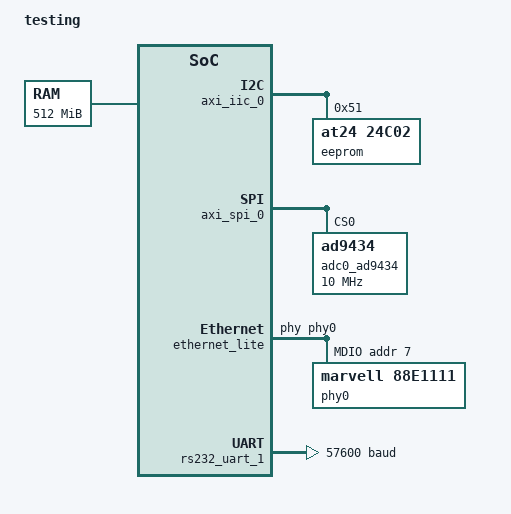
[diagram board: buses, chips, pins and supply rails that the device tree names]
/*
 * Device Tree Generator version: 1.3
 *
 * (C) Copyright 2007-2008 Xilinx, Inc.
 * (C) Copyright 2007-2009 Michal Simek
 *
 * Michal SIMEK <monstr@monstr.eu>
 *
 * This program is free software; you can redistribute it and/or
 * modify it under the terms of the GNU General Public License as
 * published by the Free Software Foundation; either version 2 of
 * the License, or (at your option) any later version.
 *
 * This program is distributed in the hope that it will be useful,
 * but WITHOUT ANY WARRANTY; without even the implied warranty of
 * MERCHANTABILITY or FITNESS FOR A PARTICULAR PURPOSE. See the
 * GNU General Public License for more details.
 *
 * You should have received a copy of the GNU General Public License
 * along with this program; if not, write to the Free Software
 * Foundation, Inc., 59 Temple Place, Suite 330, Boston,
 * MA 02111-1307 USA
 *
 * CAUTION: This file is automatically generated by libgen.
 * Version: Xilinx EDK 14.4 EDK_P.49d
 *
 * XPS project directory: device-tree_bsp_0
 */

/dts-v1/;
/ {
	#address-cells = <1>;
	#size-cells = <1>;
	compatible = "xlnx,microblaze";
	model = "testing";
	aliases {
		ethernet0 = &ethernet_lite;
		serial0 = &rs232_uart_1;
	} ;
	chosen {
		bootargs = "console=ttyS0 root=/dev/ram";
	} ;

	clocks {
// 		ad9517_ref_clk: clock@0 {
// 			#clock-cells = <0>;
// 			compatible = "fixed-clock";
// 			clock-frequency = <30720000>;
// 			clock-output-names = "refclk";
// 		};
// 		ad9517_clkin: clock@1 {
// 			#clock-cells = <0>;
// 			compatible = "fixed-clock";
// 			clock-frequency = <250000000>;
// 			clock-output-names = "clkin";
// 		};
		ad9434_clk: clock@2 {
			#clock-cells = <0>;
			compatible = "fixed-clock";
			clock-frequency = <500000000>;
			clock-output-names = "clkin";
		};

	};

	cpus {
		#address-cells = <1>;
		#cpus = <0x1>;
		#size-cells = <0>;
		microblaze_0: cpu@0 {
			clock-frequency = <100000000>;
			compatible = "xlnx,microblaze-8.30.a";
			d-cache-baseaddr = <0xc0000000>;
			d-cache-highaddr = <0xdfffffff>;
			d-cache-line-size = <0x10>;
			d-cache-size = <0x4000>;
			device_type = "cpu";
			i-cache-baseaddr = <0xc0000000>;
			i-cache-highaddr = <0xdfffffff>;
			i-cache-line-size = <0x20>;
			i-cache-size = <0x4000>;
			model = "microblaze,8.30.a";
			reg = <0>;
			timebase-frequency = <100000000>;
			xlnx,addr-tag-bits = <0xf>;
			xlnx,allow-dcache-wr = <0x1>;
			xlnx,allow-icache-wr = <0x1>;
			xlnx,area-optimized = <0x0>;
			xlnx,avoid-primitives = <0x0>;
			xlnx,branch-target-cache-size = <0x0>;
			xlnx,cache-byte-size = <0x4000>;
			xlnx,d-axi = <0x1>;
			xlnx,d-lmb = <0x1>;
			xlnx,d-plb = <0x0>;
			xlnx,data-size = <0x20>;
			xlnx,dcache-addr-tag = <0xf>;
			xlnx,dcache-always-used = <0x1>;
			xlnx,dcache-byte-size = <0x4000>;
			xlnx,dcache-data-width = <0x0>;
			xlnx,dcache-force-tag-lutram = <0x0>;
			xlnx,dcache-interface = <0x0>;
			xlnx,dcache-line-len = <0x4>;
			xlnx,dcache-use-fsl = <0x0>;
			xlnx,dcache-use-writeback = <0x0>;
			xlnx,dcache-victims = <0x0>;
			xlnx,debug-enabled = <0x1>;
			xlnx,div-zero-exception = <0x1>;
			xlnx,dynamic-bus-sizing = <0x1>;
			xlnx,ecc-use-ce-exception = <0x0>;
			xlnx,edge-is-positive = <0x1>;
			xlnx,endianness = <0x1>;
			xlnx,family = "virtex6";
			xlnx,fault-tolerant = <0x0>;
			xlnx,fpu-exception = <0x0>;
			xlnx,freq = <0x5f5e100>;
			xlnx,fsl-data-size = <0x20>;
			xlnx,fsl-exception = <0x0>;
			xlnx,fsl-links = <0x0>;
			xlnx,i-axi = <0x0>;
			xlnx,i-lmb = <0x1>;
			xlnx,i-plb = <0x0>;
			xlnx,icache-always-used = <0x1>;
			xlnx,icache-data-width = <0x0>;
			xlnx,icache-force-tag-lutram = <0x0>;
			xlnx,icache-interface = <0x0>;
			xlnx,icache-line-len = <0x8>;
			xlnx,icache-streams = <0x1>;
			xlnx,icache-use-fsl = <0x0>;
			xlnx,icache-victims = <0x8>;
			xlnx,ill-opcode-exception = <0x1>;
			xlnx,instance = "microblaze_0";
			xlnx,interconnect = <0x2>;
			xlnx,interconnect-m-axi-dc-read-issuing = <0x2>;
			xlnx,interconnect-m-axi-dc-write-issuing = <0x20>;
			xlnx,interconnect-m-axi-dp-read-issuing = <0x1>;
			xlnx,interconnect-m-axi-dp-write-issuing = <0x1>;
			xlnx,interconnect-m-axi-ic-read-issuing = <0x8>;
			xlnx,interconnect-m-axi-ip-read-issuing = <0x1>;
			xlnx,interrupt-is-edge = <0x0>;
			xlnx,lockstep-slave = <0x0>;
			xlnx,mmu-dtlb-size = <0x4>;
			xlnx,mmu-itlb-size = <0x2>;
			xlnx,mmu-privileged-instr = <0x0>;
			xlnx,mmu-tlb-access = <0x3>;
			xlnx,mmu-zones = <0x2>;
			xlnx,number-of-pc-brk = <0x1>;
			xlnx,number-of-rd-addr-brk = <0x0>;
			xlnx,number-of-wr-addr-brk = <0x0>;
			xlnx,opcode-0x0-illegal = <0x1>;
			xlnx,optimization = <0x0>;
			xlnx,pc-width = <0x20>;
			xlnx,pvr = <0x2>;
			xlnx,pvr-user1 = <0x0>;
			xlnx,pvr-user2 = <0x0>;
			xlnx,reset-msr = <0x0>;
			xlnx,sco = <0x0>;
			xlnx,stream-interconnect = <0x0>;
			xlnx,unaligned-exceptions = <0x1>;
			xlnx,use-barrel = <0x1>;
			xlnx,use-branch-target-cache = <0x0>;
			xlnx,use-dcache = <0x1>;
			xlnx,use-div = <0x1>;
			xlnx,use-ext-brk = <0x1>;
			xlnx,use-ext-nm-brk = <0x1>;
			xlnx,use-extended-fsl-instr = <0x0>;
			xlnx,use-fpu = <0x0>;
			xlnx,use-hw-mul = <0x2>;
			xlnx,use-icache = <0x1>;
			xlnx,use-interrupt = <0x1>;
			xlnx,use-mmu = <0x3>;
			xlnx,use-msr-instr = <0x1>;
			xlnx,use-pcmp-instr = <0x1>;
			xlnx,use-reorder-instr = <0x1>;
			xlnx,use-stack-protection = <0x0>;
		} ;
	} ;
	ddr3_sdram: memory@c0000000 {
		device_type = "memory";
		reg = < 0xc0000000 0x20000000 >;
	} ;
	axi4lite_0: axi@0 {
		#address-cells = <1>;
		#size-cells = <1>;
		compatible = "xlnx,axi-interconnect-1.06.a", "simple-bus";
		ranges ;
		axi_ad9434_0: cf-ad9434@73000000 {
			compatible = "xlnx,axi-ad9434-1.00.a";
			reg = < 0x73000000 0x10000 >;
			dmas = <&axi_dma_0 0>;
			dma-names = "rx";
			spibus-connected = <&adc0_ad9434>;
			xlnx,cf-buftype = <0x1>;
			xlnx,dphase-timeout = <0x8>;
			xlnx,family = "virtex6";
			xlnx,iodelay-group = "adc_if_delay_group";
			xlnx,num-mem = <0x1>;
			xlnx,num-reg = <0x1>;
			xlnx,s-axi-min-size = <0x1ff>;
			xlnx,slv-awidth = <0x20>;
			xlnx,slv-dwidth = <0x20>;
			xlnx,use-wstrb = <0x0>;
		} ;
		axi_dma_0: axidma@41e00000 {
			#address-cells = <1>;
			#size-cells = <1>;
			#dma-cells = <1>;
			compatible = "xlnx,axi-dma";
			ranges = < 0x41e00000 0x41e00000 0x10000 >;
			reg = < 0x41e00000 0x10000 >;
//			xlnx,sg-include-stscntrl-strm = <0x0>;
			dma-channel@41e00030 {
				compatible = "xlnx,axi-dma-s2mm-channel";
				interrupt-parent = <&axi_intc_0>;
				interrupts = < 3 2 >;
				xlnx,datawidth = <0x40>;
				xlnx,include-dre = <0x0>;
			} ;
		} ;

		/* LCD Display */

		axi_gpio_0: gpio@40000000 {
			compatible = "xlnx,axi-xlnx-lcd-1.00.a";
			reg = < 0x40000000 0x8 >;
			xlnx,all-inputs = <0x0>;
			xlnx,dout-default = <0x0>;
			xlnx,family = "virtex6";
			xlnx,gpio-width = <0x7>;
			xlnx,instance = "axi_gpio_0";
			xlnx,interrupt-present = <0x0>;
			xlnx,is-dual = <0x0>;
			xlnx,tri-default = <0xffffffff>;
		} ;

		axi_iic_0: i2c@40800000 {
			compatible = "xlnx,axi-iic-1.02.a", "xlnx,xps-iic-2.00.a";
			interrupt-parent = <&axi_intc_0>;
			interrupts = < 0 2 >;
			reg = < 0x40800000 0x10000 >;
			xlnx,family = "virtex6";
			xlnx,gpo-width = <0x1>;
			xlnx,iic-freq = <0x186a0>;
			xlnx,instance = "axi_iic_0";
			xlnx,s-axi-aclk-freq-hz = <0x5f5e100>;
			xlnx,scl-inertial-delay = <0x5>;
			xlnx,sda-inertial-delay = <0x5>;
			xlnx,sda-level = <0x1>;
			xlnx,ten-bit-adr = <0x0>;
			eeprom@51 {
				compatible = "at24,24c02";
				reg = <0x51>;
			};
		} ;
		axi_intc_0: interrupt-controller@41200000 {
			#interrupt-cells = <0x2>;
			compatible = "xlnx,axi-intc-1.03.a", "xlnx,xps-intc-1.00.a";
			interrupt-controller ;
			reg = < 0x41200000 0x10000 >;
			xlnx,kind-of-intr = <0x60>;
			xlnx,num-intr-inputs = <0x7>;
		} ;
		axi_spi_0: spi@40a00000 {
			compatible = "xlnx,axi-spi-1.02.a", "xlnx,xps-spi-2.00.a";
			interrupt-parent = <&axi_intc_0>;
			interrupts = < 2 2 >;
			reg = < 0x40a00000 0x10000 >;
			xlnx,family = "virtex6";
			xlnx,fifo-exist = <0x1>;
			xlnx,instance = "axi_spi_0";
			xlnx,num-ss-bits = <0x2>;
			xlnx,num-transfer-bits = <0x8>;
			xlnx,sck-ratio = <0x20>;

// 			clk_ad9517: ad9517@1 {
// 				#address-cells = <1>;
// 				#size-cells = <0>;
// 				#clock-cells = <0>;
// 				compatible = "ad9517-4";
// 				firmware = "ad9517-ad9434.stp";
// 				reg = <1>;
// 				spi-max-frequency = <10000000>;
// 				//spi-3wire;
// 				clocks = <&ad9517_ref_clk>, <&ad9517_clkin>;
// 				clock-names = "refclk", "clkin";
// 				clock-output-names = "out0", "out1", "out2", "out3", "out4", "out5", "out6", "out7";
// 			};

			adc0_ad9434: ad9434@0 {
				#address-cells = <1>;
				#size-cells = <0>;
				compatible = "ad9434";
				reg = <0>;
				spi-max-frequency = <10000000>;
				clocks = <&ad9434_clk 0>;
				clock-names = "clkin";
			};

		} ;
		axi_timer_0: timer@41c00000 {
			clock-frequency = <100000000>;
			compatible = "xlnx,axi-timer-1.03.a", "xlnx,xps-timer-1.00.a";
			interrupt-parent = <&axi_intc_0>;
			interrupts = < 4 2 >;
			reg = < 0x41c00000 0x10000 >;
			xlnx,count-width = <0x20>;
			xlnx,family = "virtex6";
			xlnx,gen0-assert = <0x1>;
			xlnx,gen1-assert = <0x1>;
			xlnx,instance = "axi_timer_0";
			xlnx,one-timer-only = <0x0>;
			xlnx,trig0-assert = <0x1>;
			xlnx,trig1-assert = <0x1>;
		} ;
		debug_module: debug@74800000 {
			compatible = "xlnx,mdm-2.10.a";
			reg = < 0x74800000 0x10000 >;
			xlnx,family = "virtex6";
			xlnx,interconnect = <0x2>;
			xlnx,jtag-chain = <0x2>;
			xlnx,mb-dbg-ports = <0x1>;
			xlnx,use-bscan = <0x0>;
			xlnx,use-uart = <0x1>;
		} ;
		ethernet_lite: ethernet@40e00000 {
			compatible = "xlnx,axi-ethernetlite-1.01.b", "xlnx,xps-ethernetlite-1.00.a";
			device_type = "network";
			interrupt-parent = <&axi_intc_0>;
			interrupts = < 5 0 >;
			local-mac-address = [ 00 0a 35 b1 22 00 ];
			phy-handle = <&phy0>;
			reg = < 0x40e00000 0x10000 >;
			xlnx,duplex = <0x1>;
			xlnx,family = "virtex6";
			xlnx,include-global-buffers = <0x0>;
			xlnx,include-internal-loopback = <0x0>;
			xlnx,include-mdio = <0x1>;
			xlnx,include-phy-constraints = <0x1>;
			xlnx,instance = "Ethernet_Lite";
			xlnx,interconnect-s-axi-read-acceptance = <0x1>;
			xlnx,interconnect-s-axi-write-acceptance = <0x1>;
			xlnx,rx-ping-pong = <0x0>;
			xlnx,s-axi-aclk-period-ps = <0x2710>;
			xlnx,s-axi-id-width = <0x1>;
			xlnx,s-axi-supports-narrow-burst = <0x0>;
			xlnx,tx-ping-pong = <0x0>;
			mdio {
				#address-cells = <1>;
				#size-cells = <0>;
				phy0: phy@7 {
					compatible = "marvell,88e1111";
					device_type = "ethernet-phy";
					reg = <7>;
				} ;
			} ;
		} ;
		rs232_uart_1: serial@40600000 {
			clock-frequency = <100000000>;
			compatible = "xlnx,axi-uartlite-1.02.a", "xlnx,xps-uartlite-1.00.a";
			current-speed = <57600>;
			device_type = "serial";
			interrupt-parent = <&axi_intc_0>;
			interrupts = < 6 0 >;
			port-number = <0>;
			reg = < 0x40600000 0x10000 >;
			xlnx,baudrate = <0xe100>;
			xlnx,data-bits = <0x8>;
			xlnx,family = "virtex6";
			xlnx,instance = "RS232_Uart_1";
			xlnx,odd-parity = <0x1>;
			xlnx,s-axi-aclk-freq-hz = <0x5f5e100>;
			xlnx,use-parity = <0x0>;
		} ;
	} ;
} ;
